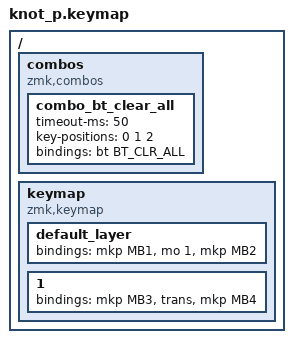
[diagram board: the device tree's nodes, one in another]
#include <behaviors.dtsi>
#include <dt-bindings/zmk/keys.h>
#include <dt-bindings/zmk/pointing.h>
#include <dt-bindings/zmk/bt.h>

/ {
  combos {
    compatible = "zmk,combos";
    combo_bt_clear_all {
      timeout-ms = <50>;
      key-positions = <0 1 2>;
      bindings = <&bt BT_CLR_ALL>;
    };
  };

  keymap {
    compatible = "zmk,keymap";
    default_layer {
      bindings = <
        &mkp MB1 &mo 1 &mkp MB2
      >;
    };
    1 {
      bindings = <
        &mkp MB3 &trans &mkp MB4 
      >;
    };
  };
};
